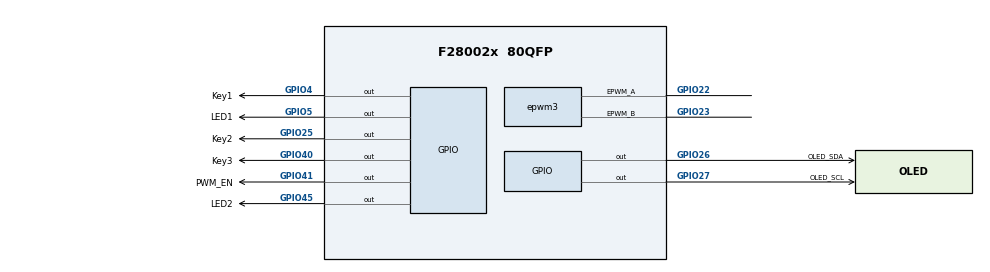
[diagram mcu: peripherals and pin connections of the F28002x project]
/**
 * @cliArgs --device "F28002x" --part "F28002x_80QFP" --package "80QFP" --context "system" --product "C2000WARE@6.00.00.00"
 * @versions {"tool":"1.25.0+4268"}
 */

/**
 * Import the modules used in this configuration.
 */
const adc       = scripting.addModule("/driverlib/adc.js", {}, false);
const adc1      = adc.addInstance();
const analog    = scripting.addModule("/driverlib/analog.js", {}, false);
const analog1   = analog.addInstance();
const cputimer  = scripting.addModule("/driverlib/cputimer.js", {}, false);
const cputimer1 = cputimer.addInstance();
const dma       = scripting.addModule("/driverlib/dma.js", {}, false);
const dma1      = dma.addInstance();
const epwm      = scripting.addModule("/driverlib/epwm.js", {}, false);
const epwm1     = epwm.addInstance();
const epwm2     = epwm.addInstance();
const epwm3     = epwm.addInstance();
const gpio      = scripting.addModule("/driverlib/gpio.js", {}, false);
const gpio1     = gpio.addInstance();
const gpio2     = gpio.addInstance();
const gpio3     = gpio.addInstance();
const gpio4     = gpio.addInstance();
const gpio5     = gpio.addInstance();
const gpio6     = gpio.addInstance();
const gpio7     = gpio.addInstance();
const gpio8     = gpio.addInstance();

/**
 * Write custom configuration values to the imported modules.
 */
adc1.adcClockPrescaler              = "ADC_CLK_DIV_2_0";
adc1.soc0SampleWindow               = 15;
adc1.soc0Trigger                    = "ADC_TRIGGER_EPWM2_SOCA";
adc1.registerInterrupts             = ["1"];
adc1.enabledInts                    = ["ADC_INT_NUMBER1"];
adc1.interruptPulseMode             = "ADC_PULSE_END_OF_CONV";
adc1.$name                          = "ADC_A";
adc1.enableInterrupt1               = true;
adc1.enableInterrupt1ContinuousMode = true;
adc1.soc3SampleWindow               = 15;
adc1.soc0Channel                    = "ADC_CH_ADCIN14";
adc1.enabledSOCs                    = ["ADC_SOC_NUMBER0","ADC_SOC_NUMBER1","ADC_SOC_NUMBER2"];
adc1.soc1Channel                    = "ADC_CH_ADCIN15";
adc1.soc1Trigger                    = "ADC_TRIGGER_EPWM2_SOCA";
adc1.soc1SampleWindow               = 15;
adc1.soc2Channel                    = "ADC_CH_ADCIN1";
adc1.soc2Trigger                    = "ADC_TRIGGER_EPWM2_SOCA";
adc1.soc2SampleWindow               = 15;
adc1.adcInt1.enableInterrupt        = true;

analog1.$name            = "myANALOGPinMux0";
analog1.useCase          = "CUSTOM";
analog1.useInterfacePins = ["A0/C15","A1","A10/C10","A11/C0","A12/C1","A14/C4","A15/C7","A2/C9","A3/C5/VDAC","A4/C14","A5/C2","A6","A7/C3","A8/C11","A9/C8","C6"];
adc1.analog              = analog1;

const multiplier1         = system.clockTree["PLL_IMULT"];
multiplier1.multiplyValue = 25;

const pinFunction2     = system.clockTree["XTAL"];
pinFunction2.XTAL_Freq = 16;

cputimer1.$name          = "CpuTimer0";
cputimer1.timerPrescaler = 99;
cputimer1.timerPeriod    = 999;
cputimer1.emulationMode  = "CPUTIMER_EMULATIONMODE_RUNFREE";
cputimer1.startTimer     = true;

dma1.enableTriggers         = true;
dma1.useInterrupts          = true;
dma1.registerInterrupts     = true;
dma1.enableInterrupts       = true;
dma1.interruptMode          = "DMA_INT_AT_END";
dma1.emulationMode          = "DMA_EMULATION_FREE_RUN";
dma1.continuousModeConfig   = "DMA_CFG_CONTINUOUS_ENABLE";
dma1.burstSize              = 16;
dma1.transferSize           = 2;
dma1.srcAddressInputMode    = "VARIABLE";
dma1.srcAddressVariable     = "Dma_SourceAddr";
dma1.destAddressInputMode   = "VARIABLE";
dma1.destAddressVariable    = "Dma_DestinationAddr";
dma1.srcBurstStep           = 1;
dma1.srcTransferStep        = -15;
dma1.destBurstStep          = 1;
dma1.startChannel           = true;
dma1.destWrapSize           = 32;
dma1.destTransferStep       = 1;
dma1.srcWrapSize            = 16;
dma1.$name                  = "DMA_A";
dma1.triggerSource          = "DMA_TRIGGER_ADCA1";
dma1.dmaInt.enableInterrupt = true;

epwm1.$name                                                      = "ePWM_Ap";
epwm1.epwmTimebase_hsClockDiv                                    = "EPWM_HSCLOCK_DIVIDER_1";
epwm1.epwmTimebase_period                                        = 2500;
epwm1.epwmTimebase_counterMode                                   = "EPWM_COUNTER_MODE_UP_DOWN";
epwm1.epwmTimebase_counterModeAfterSync                          = "EPWM_COUNT_MODE_UP_AFTER_SYNC";
epwm1.epwmCounterCompare_cmpA                                    = 1000;
epwm1.epwmCounterCompare_shadowLoadModeCMPA                      = "EPWM_COMP_LOAD_ON_CNTR_ZERO_PERIOD";
epwm1.epwmActionQualifier_EPWM_AQ_OUTPUT_A_ON_TIMEBASE_DOWN_CMPA = "EPWM_AQ_OUTPUT_HIGH";
epwm1.epwmActionQualifier_EPWM_AQ_OUTPUT_A_ON_TIMEBASE_UP_CMPA   = "EPWM_AQ_OUTPUT_LOW";
epwm1.epwmDeadband_polarityFED                                   = "EPWM_DB_POLARITY_ACTIVE_LOW";
epwm1.epwmDeadband_enableRED                                     = true;
epwm1.epwmDeadband_enableFED                                     = true;
epwm1.epwmDeadband_delayRED                                      = 100;
epwm1.epwmDeadband_delayFED                                      = 100;
epwm1.epwmTripZone_EPWM_TZ_ACTION_EVENT_TZA                      = "EPWM_TZ_ACTION_LOW";
epwm1.epwmTripZone_EPWM_TZ_ACTION_EVENT_TZB                      = "EPWM_TZ_ACTION_LOW";
epwm1.epwmTripZone_EPWM_TZ_ACTION_EVENT_DCAEVT1                  = "EPWM_TZ_ACTION_DISABLE";
epwm1.epwmTripZone_EPWM_TZ_ACTION_EVENT_DCAEVT2                  = "EPWM_TZ_ACTION_DISABLE";
epwm1.epwmTripZone_EPWM_TZ_ACTION_EVENT_DCBEVT1                  = "EPWM_TZ_ACTION_DISABLE";
epwm1.epwmTripZone_EPWM_TZ_ACTION_EVENT_DCBEVT2                  = "EPWM_TZ_ACTION_DISABLE";
epwm1.epwmTripZone_oneShotSource                                 = ["EPWM_TZ_SIGNAL_DCAEVT1"];
epwm1.epwmTripZone_registerInterrupts                            = true;
epwm1.epwmTripZone_tzInterruptSource                             = ["EPWM_TZ_INTERRUPT_DCAEVT1"];
epwm1.epwmEventTrigger_EPWM_SOC_A_triggerEnable                  = true;
epwm1.epwmEventTrigger_EPWM_SOC_B_triggerEnable                  = true;
epwm1.epwmEventTrigger_EPWM_SOC_A_triggerSource                  = "EPWM_SOC_TBCTR_ZERO_OR_PERIOD";
epwm1.epwmEventTrigger_EPWM_SOC_B_triggerSource                  = "EPWM_SOC_TBCTR_ZERO";
epwm1.epwmTimebase_syncInPulseSource                             = "EPWM_SYNC_IN_PULSE_SRC_DISABLE";
epwm1.epwmTimebase_syncOutPulseMode                              = ["EPWM_SYNC_OUT_PULSE_ON_CNTR_ZERO"];
epwm1.hrpwm_syncSource                                           = "HRPWM_PWMSYNC_SOURCE_ZERO";
epwm1.epwmEventTrigger_EPWM_SOC_A_triggerEventPrescalar          = "1";
epwm1.epwm.$assign                                               = "EPWM2";
epwm1.epwmTZInt.enableInterrupt                                  = true;

epwm2.$name                                             = "ePWM_Trigger";
epwm2.epwmTimebase_hsClockDiv                           = "EPWM_HSCLOCK_DIVIDER_1";
epwm2.epwmTimebase_counterMode                          = "EPWM_COUNTER_MODE_UP_DOWN";
epwm2.epwmTimebase_counterModeAfterSync                 = "EPWM_COUNT_MODE_UP_AFTER_SYNC";
epwm2.epwmEventTrigger_EPWM_SOC_A_triggerEnable         = true;
epwm2.epwmEventTrigger_EPWM_SOC_B_triggerEnable         = true;
epwm2.epwmEventTrigger_EPWM_SOC_A_triggerSource         = "EPWM_SOC_TBCTR_ZERO_OR_PERIOD";
epwm2.epwmTimebase_period                               = 500;
epwm2.epwmEventTrigger_EPWM_SOC_A_triggerEventPrescalar = "5";
epwm2.epwmEventTrigger_EPWM_SOC_B_triggerEventPrescalar = "5";
epwm2.epwmEventTrigger_EPWM_SOC_B_triggerSource         = "EPWM_SOC_TBCTR_ZERO";
epwm2.epwmTimebase_syncInPulseSource                    = "EPWM_SYNC_IN_PULSE_SRC_SYNCOUT_EPWM2";
epwm2.hrpwm_syncSource                                  = "HRPWM_PWMSYNC_SOURCE_ZERO";
epwm2.epwmTimebase_phaseEnable                          = true;
epwm2.epwmTimebase_phaseShift                           = 2;
epwm2.epwm.$assign                                      = "EPWM5";

epwm3.epwmTimebase_hsClockDiv                                    = "EPWM_HSCLOCK_DIVIDER_1";
epwm3.epwmTimebase_period                                        = 2500;
epwm3.epwmTimebase_counterMode                                   = "EPWM_COUNTER_MODE_UP_DOWN";
epwm3.epwmTimebase_counterModeAfterSync                          = "EPWM_COUNT_MODE_UP_AFTER_SYNC";
epwm3.epwmCounterCompare_cmpA                                    = 1000;
epwm3.epwmCounterCompare_shadowLoadModeCMPA                      = "EPWM_COMP_LOAD_ON_CNTR_ZERO_PERIOD";
epwm3.epwmActionQualifier_EPWM_AQ_OUTPUT_A_ON_TIMEBASE_DOWN_CMPA = "EPWM_AQ_OUTPUT_HIGH";
epwm3.epwmActionQualifier_EPWM_AQ_OUTPUT_A_ON_TIMEBASE_UP_CMPA   = "EPWM_AQ_OUTPUT_LOW";
epwm3.epwmDeadband_polarityFED                                   = "EPWM_DB_POLARITY_ACTIVE_LOW";
epwm3.epwmDeadband_enableRED                                     = true;
epwm3.epwmDeadband_enableFED                                     = true;
epwm3.epwmDeadband_delayRED                                      = 100;
epwm3.epwmDeadband_delayFED                                      = 100;
epwm3.epwmTripZone_EPWM_TZ_ACTION_EVENT_TZA                      = "EPWM_TZ_ACTION_LOW";
epwm3.epwmTripZone_EPWM_TZ_ACTION_EVENT_TZB                      = "EPWM_TZ_ACTION_LOW";
epwm3.epwmTripZone_EPWM_TZ_ACTION_EVENT_DCAEVT1                  = "EPWM_TZ_ACTION_DISABLE";
epwm3.epwmTripZone_EPWM_TZ_ACTION_EVENT_DCAEVT2                  = "EPWM_TZ_ACTION_DISABLE";
epwm3.epwmTripZone_EPWM_TZ_ACTION_EVENT_DCBEVT1                  = "EPWM_TZ_ACTION_DISABLE";
epwm3.epwmTripZone_EPWM_TZ_ACTION_EVENT_DCBEVT2                  = "EPWM_TZ_ACTION_DISABLE";
epwm3.epwmTripZone_oneShotSource                                 = ["EPWM_TZ_SIGNAL_DCAEVT1"];
epwm3.epwmEventTrigger_EPWM_SOC_A_triggerEnable                  = true;
epwm3.epwmEventTrigger_EPWM_SOC_B_triggerEnable                  = true;
epwm3.epwmEventTrigger_EPWM_SOC_A_triggerSource                  = "EPWM_SOC_TBCTR_ZERO_OR_PERIOD";
epwm3.epwmEventTrigger_EPWM_SOC_B_triggerSource                  = "EPWM_SOC_TBCTR_ZERO";
epwm3.$name                                                      = "ePWM_Bp";
epwm3.epwmTimebase_phaseEnable                                   = true;
epwm3.epwmTimebase_phaseShift                                    = 2;
epwm3.epwmTimebase_syncInPulseSource                             = "EPWM_SYNC_IN_PULSE_SRC_SYNCOUT_EPWM2";
epwm3.hrpwm_syncSource                                           = "HRPWM_PWMSYNC_SOURCE_ZERO";
epwm3.epwm.$assign                                               = "EPWM4";
epwm3.epwm.epwm_aPin.$assign                                     = "GPIO22";
epwm3.epwm.epwm_bPin.$assign                                     = "GPIO23";

gpio1.$name           = "LED1";
gpio1.direction       = "GPIO_DIR_MODE_OUT";
gpio1.padConfig       = "PULLUP";
gpio1.gpioPin.$assign = "GPIO5";

gpio2.$name           = "LED2";
gpio2.direction       = "GPIO_DIR_MODE_OUT";
gpio2.padConfig       = "PULLUP";
gpio2.gpioPin.$assign = "GPIO45";

gpio3.$name             = "PWM_EN";
gpio3.direction         = "GPIO_DIR_MODE_OUT";
gpio3.padConfig         = "PULLUP";
gpio3.writeInitialValue = true;
gpio3.initialValue      = 1;
gpio3.gpioPin.$assign   = "GPIO41";

gpio4.$name           = "Key1";
gpio4.gpioPin.$assign = "GPIO4";

gpio5.$name           = "Key2";
gpio5.gpioPin.$assign = "GPIO25";

gpio6.$name           = "Key3";
gpio6.gpioPin.$assign = "GPIO40";

gpio7.direction         = "GPIO_DIR_MODE_OUT";
gpio7.padConfig         = "PULLUP";
gpio7.$name             = "OLED_SCL";
gpio7.writeInitialValue = true;
gpio7.initialValue      = 1;
gpio7.gpioPin.$assign   = "GPIO27";

gpio8.direction         = "GPIO_DIR_MODE_OUT";
gpio8.padConfig         = "PULLUP";
gpio8.writeInitialValue = true;
gpio8.initialValue      = 1;
gpio8.$name             = "OLED_SDA";
gpio8.gpioPin.$assign   = "GPIO26";

/**
 * Pinmux solution for unlocked pins/peripherals. This ensures that minor changes to the automatic solver in a future
 * version of the tool will not impact the pinmux you originally saw.  These lines can be completely deleted in order to
 * re-solve from scratch.
 */
analog1.analog.$suggestSolution                  = "ANALOG";
analog1.analog["a0/c15Pin"].$suggestSolution     = "A0/C15";
analog1.analog.a1Pin.$suggestSolution            = "A1";
analog1.analog["a10/c10Pin"].$suggestSolution    = "A10/C10";
analog1.analog["a11/c0Pin"].$suggestSolution     = "A11/C0";
analog1.analog["a12/c1Pin"].$suggestSolution     = "A12/C1";
analog1.analog["a14/c4Pin"].$suggestSolution     = "A14/C4";
analog1.analog["a15/c7Pin"].$suggestSolution     = "A15/C7";
analog1.analog["a2/c9Pin"].$suggestSolution      = "A2/C9";
analog1.analog["a3/c5/vdacPin"].$suggestSolution = "A3/C5/VDAC";
analog1.analog["a4/c14Pin"].$suggestSolution     = "A4/C14";
analog1.analog["a5/c2Pin"].$suggestSolution      = "A5/C2";
analog1.analog.a6Pin.$suggestSolution            = "A6";
analog1.analog["a7/c3Pin"].$suggestSolution      = "A7/C3";
analog1.analog["a8/c11Pin"].$suggestSolution     = "A8/C11";
analog1.analog["a9/c8Pin"].$suggestSolution      = "A9/C8";
analog1.analog.c6Pin.$suggestSolution            = "C6";
epwm1.epwm.epwm_aPin.$suggestSolution            = "GPIO2";
epwm1.epwm.epwm_bPin.$suggestSolution            = "GPIO3";
epwm2.epwm.epwm_aPin.$suggestSolution            = "GPIO16";
epwm2.epwm.epwm_bPin.$suggestSolution            = "GPIO17";
